VERSION ""

NS_ :

BS_:

BU_: TestNode
VAL_TABLE_ OperatingStatus 3 "Not Available" 2 "Not Operable" 1 "Derated Operation" 0 "Normal Operation" ;
VAL_TABLE_ ServiceIndicator 3 "Not Available" 2 "Reserved" 1 "Service Required" 0 "Service Not Required" ;
VAL_TABLE_ CommandStatus 3 "Not Available" 2 "Default Command" 1 "External Command" 0 "Internal Command" ;
VAL_TABLE_ StatusReasonLegacy 12 "Operating at Max Control Effort" 11 "Operating at Amp Limit" 10 "Unused" 9 "Over-Temp Protection Shutdown" 8 "Unused" 7 "Under-Voltage Protection Shutdn" 6 "Over Voltage Protection Shutdown" 5 "Unused" 4 "Unable to Start" 3 "Unused" 2 "Unused" 1 "Unused" 0 "OK/ Normal Operation" ;
VAL_TABLE_ StatusReason 6 "Speed Limit due to max cap" 5 "Speed Limit due to Amp Limit" 4 "Over-Temp Protection Shutdown" 3 "Under-Voltage Protection Shutdwn" 2 "Over-Voltage Protection Shutdown" 1 "Unable to Start" 0 "Normal Operation" ;
VAL_TABLE_ PowerHold 3 "Not Used" 2 "Reserved" 1 "Power On" 0 "Power Off" ;
VAL_TABLE_ OnOffDir 3 "Not Used" 2 "Motor On: Reverse" 1 "Motor On: Normal/Default Dir" 0 "Motor Off" ;

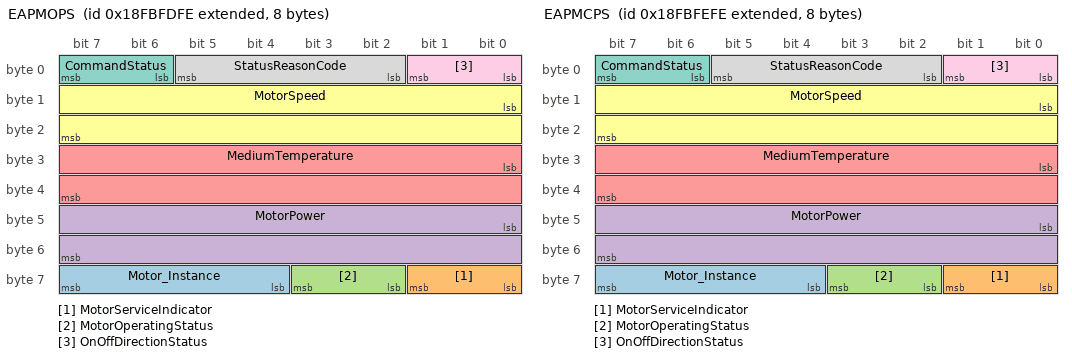
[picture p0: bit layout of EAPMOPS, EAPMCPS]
BO_ 2566651390 EAPMOPS: 8 Vector__XXX
 SG_ Motor_Instance : 60|4@1+ (1,0) [0|0] "" Vector__XXX
 SG_ MotorServiceIndicator : 56|2@1+ (1,0) [0|0] "" Vector__XXX
 SG_ MotorOperatingStatus : 58|2@1+ (1,0) [0|0] "" Vector__XXX
 SG_ MotorPower : 40|16@1+ (0.5,0) [0|0] "W" Vector__XXX
 SG_ MediumTemperature : 24|16@1+ (0.03125,-273) [0|0] "C" Vector__XXX
 SG_ MotorSpeed : 8|16@1+ (0.5,0) [0|0] "RPM" Vector__XXX
 SG_ CommandStatus : 6|2@1+ (1,0) [0|0] "" Vector__XXX
 SG_ StatusReasonCode : 2|4@1+ (1,0) [0|0] "" Vector__XXX
 SG_ OnOffDirectionStatus : 0|2@1+ (1,0) [0|0] "" Vector__XXX

BO_ 2566651646 EAPMCPS: 8 Vector__XXX
 SG_ Motor_Instance : 60|4@1+ (1,0) [0|0] "" Vector__XXX
 SG_ MotorServiceIndicator : 56|2@1+ (1,0) [0|0] "" Vector__XXX
 SG_ MotorOperatingStatus : 58|2@1+ (1,0) [0|0] "" Vector__XXX
 SG_ MotorPower : 40|16@1+ (0.5,0) [0|0] "W" Vector__XXX
 SG_ MediumTemperature : 24|16@1+ (0.03125,-273) [0|0] "C" Vector__XXX
 SG_ MotorSpeed : 8|16@1+ (0.5,0) [0|0] "RPM" Vector__XXX
 SG_ CommandStatus : 6|2@1+ (1,0) [0|0] "" Vector__XXX
 SG_ StatusReasonCode : 2|4@1+ (1,0) [0|0] "" Vector__XXX
 SG_ OnOffDirectionStatus : 0|2@1+ (1,0) [0|0] "" Vector__XXX

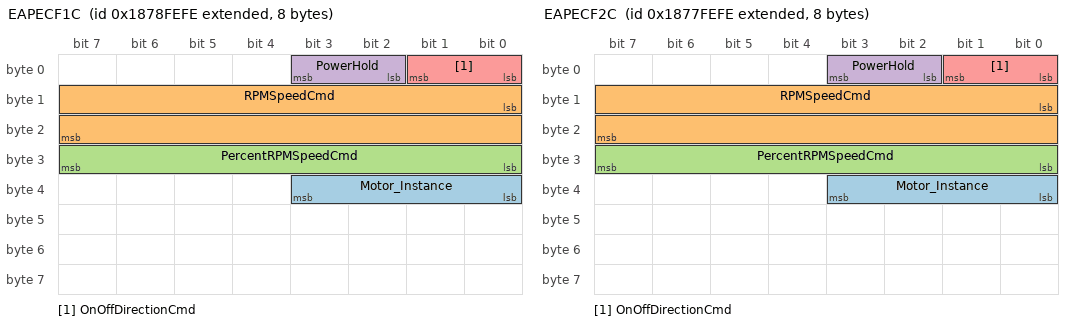
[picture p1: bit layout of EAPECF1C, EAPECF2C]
BO_ 2558066430 EAPECF1C: 8 Vector__XXX
 SG_ Motor_Instance : 32|4@1+ (1,0) [0|0] "" Vector__XXX
 SG_ RPMSpeedCmd : 8|16@1+ (0.5,0) [0|32127.5] "RPM" Vector__XXX
 SG_ PercentRPMSpeedCmd : 24|8@1+ (0.5,0) [0|125] "Pct" Vector__XXX
 SG_ PowerHold : 2|2@1+ (1,0) [0|3] "" Vector__XXX
 SG_ OnOffDirectionCmd : 0|2@1+ (1,0) [0|3] "" Vector__XXX

BO_ 2558000894 EAPECF2C: 8 Vector__XXX
 SG_ Motor_Instance : 32|4@1+ (1,0) [0|0] "" Vector__XXX
 SG_ RPMSpeedCmd : 8|16@1+ (0.5,0) [0|32127.5] "RPM" Vector__XXX
 SG_ PercentRPMSpeedCmd : 24|8@1+ (0.5,0) [0|125] "Pct" Vector__XXX
 SG_ PowerHold : 2|2@1+ (1,0) [0|3] "" Vector__XXX
 SG_ OnOffDirectionCmd : 0|2@1+ (1,0) [0|3] "" Vector__XXX

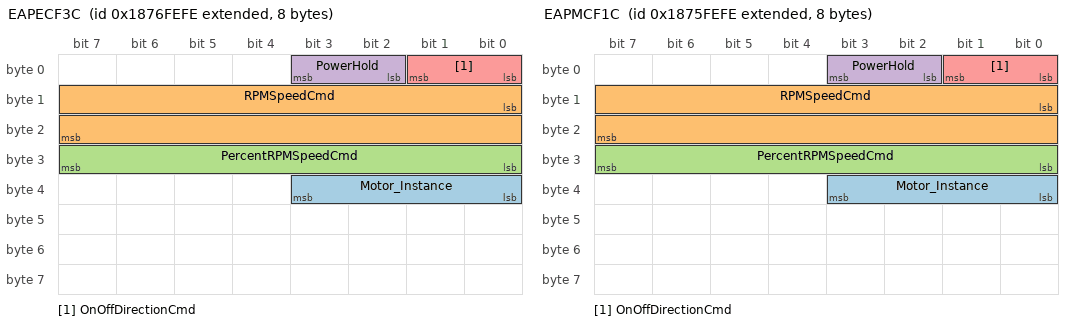
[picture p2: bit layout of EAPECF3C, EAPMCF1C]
BO_ 2557935358 EAPECF3C: 8 Vector__XXX
 SG_ Motor_Instance : 32|4@1+ (1,0) [0|0] "" Vector__XXX
 SG_ RPMSpeedCmd : 8|16@1+ (0.5,0) [0|32127.5] "RPM" Vector__XXX
 SG_ PercentRPMSpeedCmd : 24|8@1+ (0.5,0) [0|125] "Pct" Vector__XXX
 SG_ PowerHold : 2|2@1+ (1,0) [0|3] "" Vector__XXX
 SG_ OnOffDirectionCmd : 0|2@1+ (1,0) [0|3] "" Vector__XXX

BO_ 2557869822 EAPMCF1C: 8 Vector__XXX
 SG_ Motor_Instance : 32|4@1+ (1,0) [0|0] "" Vector__XXX
 SG_ RPMSpeedCmd : 8|16@1+ (0.5,0) [0|32127.5] "RPM" Vector__XXX
 SG_ PercentRPMSpeedCmd : 24|8@1+ (0.5,0) [0|125] "Pct" Vector__XXX
 SG_ PowerHold : 2|2@1+ (1,0) [0|3] "" Vector__XXX
 SG_ OnOffDirectionCmd : 0|2@1+ (1,0) [0|3] "" Vector__XXX

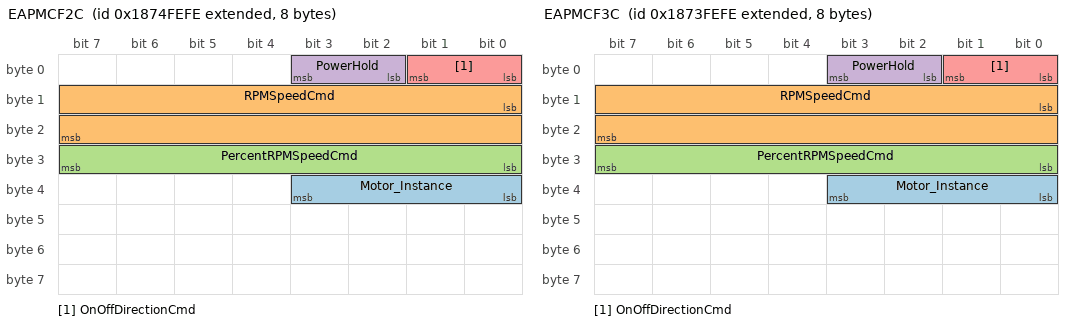
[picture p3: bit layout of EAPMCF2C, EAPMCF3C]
BO_ 2557804286 EAPMCF2C: 8 Vector__XXX
 SG_ Motor_Instance : 32|4@1+ (1,0) [0|0] "" Vector__XXX
 SG_ RPMSpeedCmd : 8|16@1+ (0.5,0) [0|32127.5] "RPM" Vector__XXX
 SG_ PercentRPMSpeedCmd : 24|8@1+ (0.5,0) [0|125] "Pct" Vector__XXX
 SG_ PowerHold : 2|2@1+ (1,0) [0|3] "" Vector__XXX
 SG_ OnOffDirectionCmd : 0|2@1+ (1,0) [0|3] "" Vector__XXX

BO_ 2557738750 EAPMCF3C: 8 Vector__XXX
 SG_ Motor_Instance : 32|4@1+ (1,0) [0|0] "" Vector__XXX
 SG_ RPMSpeedCmd : 8|16@1+ (0.5,0) [0|32127.5] "RPM" Vector__XXX
 SG_ PercentRPMSpeedCmd : 24|8@1+ (0.5,0) [0|125] "Pct" Vector__XXX
 SG_ PowerHold : 2|2@1+ (1,0) [0|3] "" Vector__XXX
 SG_ OnOffDirectionCmd : 0|2@1+ (1,0) [0|3] "" Vector__XXX

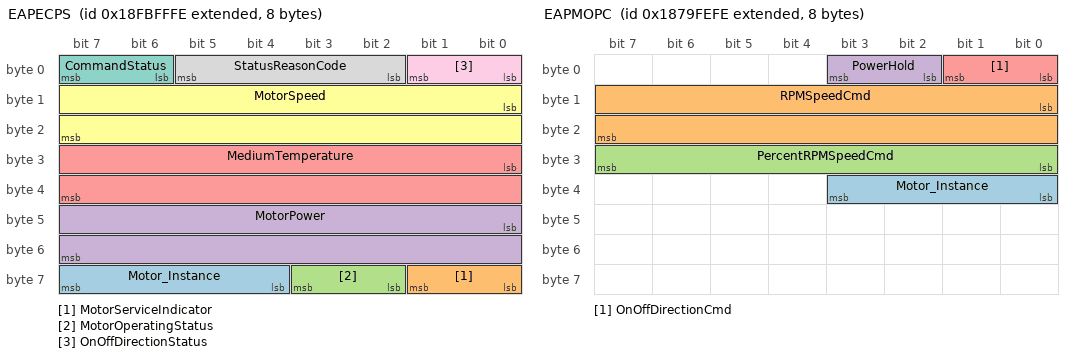
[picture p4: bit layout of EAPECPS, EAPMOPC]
BO_ 2566651902 EAPECPS: 8 Vector__XXX
 SG_ Motor_Instance : 60|4@1+ (1,0) [0|0] "" Vector__XXX
 SG_ MotorServiceIndicator : 56|2@1+ (1,0) [0|0] "" Vector__XXX
 SG_ MotorOperatingStatus : 58|2@1+ (1,0) [0|0] "" Vector__XXX
 SG_ MotorPower : 40|16@1+ (0.5,0) [0|0] "W" Vector__XXX
 SG_ MediumTemperature : 24|16@1+ (0.03125,-273) [0|0] "C" Vector__XXX
 SG_ MotorSpeed : 8|16@1+ (0.5,0) [0|0] "RPM" Vector__XXX
 SG_ CommandStatus : 6|2@1+ (1,0) [0|0] "" Vector__XXX
 SG_ StatusReasonCode : 2|4@1+ (1,0) [0|0] "" Vector__XXX
 SG_ OnOffDirectionStatus : 0|2@1+ (1,0) [0|0] "" Vector__XXX

BO_ 2558131966 EAPMOPC: 8 Vector__XXX
 SG_ Motor_Instance : 32|4@1+ (1,0) [0|0] "" Vector__XXX
 SG_ RPMSpeedCmd : 8|16@1+ (0.5,0) [0|32127.5] "RPM" Vector__XXX
 SG_ PercentRPMSpeedCmd : 24|8@1+ (0.5,0) [0|125] "Pct" Vector__XXX
 SG_ PowerHold : 2|2@1+ (1,0) [0|3] "" Vector__XXX
 SG_ OnOffDirectionCmd : 0|2@1+ (1,0) [0|3] "" Vector__XXX

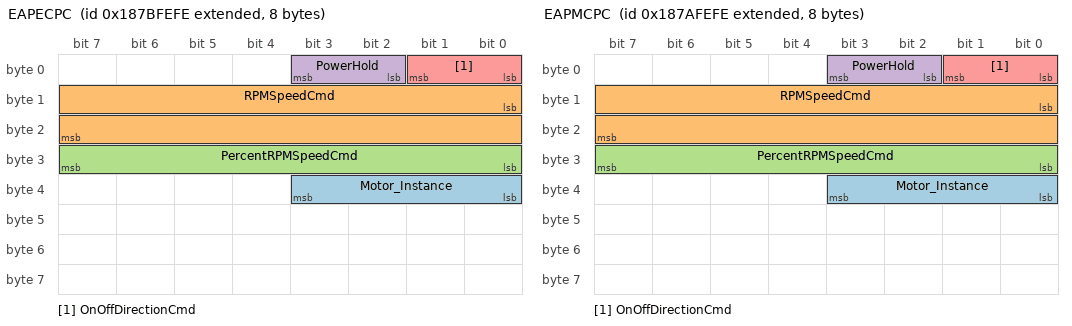
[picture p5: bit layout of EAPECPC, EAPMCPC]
BO_ 2558263038 EAPECPC: 8 Vector__XXX
 SG_ Motor_Instance : 32|4@1+ (1,0) [0|0] "" Vector__XXX
 SG_ RPMSpeedCmd : 8|16@1+ (0.5,0) [0|32127.5] "RPM" Vector__XXX
 SG_ PercentRPMSpeedCmd : 24|8@1+ (0.5,0) [0|125] "Pct" Vector__XXX
 SG_ PowerHold : 2|2@1+ (1,0) [0|3] "" Vector__XXX
 SG_ OnOffDirectionCmd : 0|2@1+ (1,0) [0|3] "" Vector__XXX

BO_ 2558197502 EAPMCPC: 8 Vector__XXX
 SG_ Motor_Instance : 32|4@1+ (1,0) [0|0] "" Vector__XXX
 SG_ RPMSpeedCmd : 8|16@1+ (0.5,0) [0|32127.5] "RPM" Vector__XXX
 SG_ PercentRPMSpeedCmd : 24|8@1+ (0.5,0) [0|127.5] "Pct" Vector__XXX
 SG_ PowerHold : 2|2@1+ (1,0) [0|3] "" Vector__XXX
 SG_ OnOffDirectionCmd : 0|2@1+ (1,0) [0|3] "" Vector__XXX

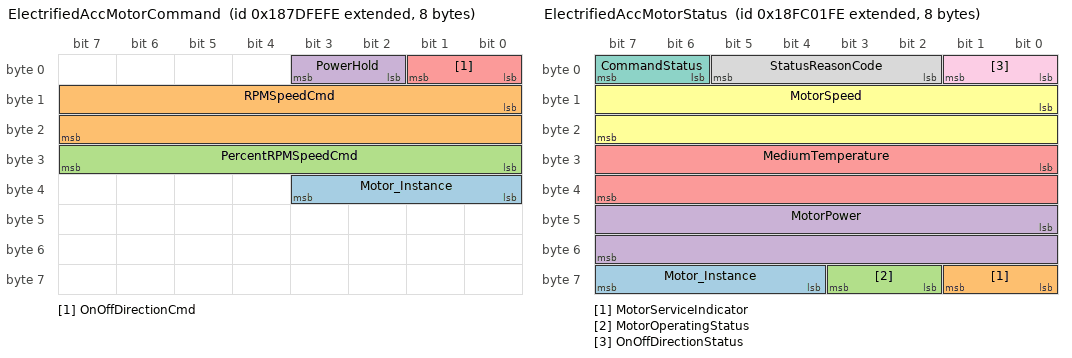
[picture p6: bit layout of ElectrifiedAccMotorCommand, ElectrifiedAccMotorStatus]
BO_ 2558394110 ElectrifiedAccMotorCommand: 8 TestNode
 SG_ Motor_Instance : 32|4@1+ (1,0) [0|0] "" Vector__XXX
 SG_ RPMSpeedCmd : 8|16@1+ (0.5,0) [0|32127.5] "RPM" Vector__XXX
 SG_ PercentRPMSpeedCmd : 24|8@1+ (0.5,0) [0|125] "Pct" Vector__XXX
 SG_ PowerHold : 2|2@1+ (1,0) [0|3] "" Vector__XXX
 SG_ OnOffDirectionCmd : 0|2@1+ (1,0) [0|3] "" Vector__XXX

BO_ 2566652414 ElectrifiedAccMotorStatus: 8 Vector__XXX
 SG_ Motor_Instance : 60|4@1+ (1,0) [0|0] "" Vector__XXX
 SG_ MotorServiceIndicator : 56|2@1+ (1,0) [0|0] "" Vector__XXX
 SG_ MotorOperatingStatus : 58|2@1+ (1,0) [0|0] "" Vector__XXX
 SG_ MotorPower : 40|16@1+ (0.5,0) [0|0] "W" Vector__XXX
 SG_ MediumTemperature : 24|16@1+ (0.03125,-273) [0|0] "C" Vector__XXX
 SG_ MotorSpeed : 8|16@1+ (0.5,0) [0|0] "RPM" Vector__XXX
 SG_ CommandStatus : 6|2@1+ (1,0) [0|0] "" Vector__XXX
 SG_ StatusReasonCode : 2|4@1+ (1,0) [0|0] "" Vector__XXX
 SG_ OnOffDirectionStatus : 0|2@1+ (1,0) [0|0] "" Vector__XXX

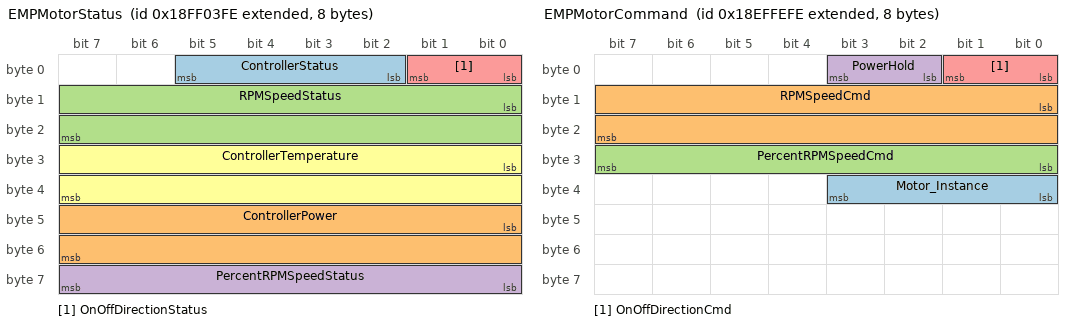
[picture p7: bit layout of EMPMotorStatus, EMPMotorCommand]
BO_ 2566849534 EMPMotorStatus: 8 Vector__XXX
 SG_ ControllerStatus : 2|4@1+ (1,0) [0|0] "" Vector__XXX
 SG_ ControllerPower : 40|16@1+ (1,0) [0|60000] "W" Vector__XXX
 SG_ RPMSpeedStatus : 8|16@1+ (0.5,0) [0|32127.5] "RPM" Vector__XXX
 SG_ PercentRPMSpeedStatus : 56|8@1+ (0.5,0) [0|125] "Pct" Vector__XXX
 SG_ OnOffDirectionStatus : 0|2@1+ (1,0) [0|3] "" Vector__XXX
 SG_ ControllerTemperature : 24|16@1+ (0.03125,-273) [-273|1734.96875] "C" Vector__XXX

BO_ 2565865214 EMPMotorCommand: 8 Vector__XXX
 SG_ Motor_Instance : 32|4@1+ (1,0) [0|0] "" Vector__XXX
 SG_ RPMSpeedCmd : 8|16@1+ (0.5,0) [0|32127.5] "RPM" Vector__XXX
 SG_ PercentRPMSpeedCmd : 24|8@1+ (0.5,0) [0|125] "Pct" Vector__XXX
 SG_ PowerHold : 2|2@1+ (1,0) [0|3] "" Vector__XXX
 SG_ OnOffDirectionCmd : 0|2@1+ (1,0) [0|3] "" Vector__XXX

BA_DEF_ SG_  "SigType" ENUM  "Default","Range","RangeSigned","ASCII","Discrete","Control","ReferencePGN","DTC","StringDelimiter","StringLength","StringLengthControl";
BA_DEF_ SG_  "GenSigEVName" STRING ;
BA_DEF_ SG_  "GenSigILSupport" ENUM  "Yes","No";
BA_DEF_ SG_  "GenSigSendType" ENUM  "Cyclic","OnWrite","reserved","OnChange","reserved","reserved","reserved","NoSigSendType";
BA_DEF_ SG_  "GenSigStartValue" INT 0 10000;
BA_DEF_ BO_  "GenMsgILSupport" ENUM  "Yes","No";
BA_DEF_ BU_  "NmStationAddress" INT 0 255;
BA_DEF_ BO_  "GenMsgSendType" ENUM  "cyclic","reserved","cyclicIfActive","reserved","reserved","reserved","reserved","reserved","noMsgSendType";
BA_DEF_ BO_  "GenMsgRequestable" INT 0 1;
BA_DEF_  "DBName" STRING ;
BA_DEF_  "BusType" STRING ;
BA_DEF_  "ProtocolType" STRING ;
BA_DEF_ BO_  "VFrameFormat" ENUM  "StandardCAN","ExtendedCAN","reserved","J1939PG";
BA_DEF_DEF_  "SigType" "Default";
BA_DEF_DEF_  "GenSigEVName" "Env@Nodename_@Signame";
BA_DEF_DEF_  "GenSigILSupport" "Yes";
BA_DEF_DEF_  "GenSigSendType" "NoSigSendType";
BA_DEF_DEF_  "GenSigStartValue" 0;
BA_DEF_DEF_  "GenMsgILSupport" "Yes";
BA_DEF_DEF_  "NmStationAddress" 254;
BA_DEF_DEF_  "GenMsgSendType" "noMsgSendType";
BA_DEF_DEF_  "GenMsgRequestable" 1;
BA_DEF_DEF_  "DBName" "";
BA_DEF_DEF_  "BusType" "CAN";
BA_DEF_DEF_  "ProtocolType" "J1939";
BA_DEF_DEF_  "VFrameFormat" "J1939PG";
BA_ "DBName" "EMP_CAN3";
BA_ "NmStationAddress" BU_ TestNode 119;
BA_ "GenSigStartValue" SG_ 2566651390 MediumTemperature 8736;
BA_ "GenSigStartValue" SG_ 2566651646 MediumTemperature 8736;
BA_ "GenSigStartValue" SG_ 2566651902 MediumTemperature 8736;
BA_ "GenSigStartValue" SG_ 2566652414 MediumTemperature 8736;
BA_ "GenSigStartValue" SG_ 2566849534 ControllerTemperature 8736;
VAL_ 2566651390 MotorServiceIndicator 3 "Not Available" 2 "Reserved" 1 "Service Required" 0 "Service Not Required" ;
VAL_ 2566651390 MotorOperatingStatus 3 "Not Available" 2 "Not Operable" 1 "Derated Operation" 0 "Normal Operation" ;
VAL_ 2566651390 CommandStatus 3 "Not Available" 2 "Default Command" 1 "External Command" 0 "Internal Command" ;
VAL_ 2566651390 StatusReasonCode 7 "Speed Limit for stall protect" 6 "Speed Limit due to max cap" 5 "Speed Limit due to Amp Limit" 4 "Over-Temp Protection Shutdown" 3 "Under-Voltage Protection Shutdwn" 2 "Over-Voltage Protection Shutdown" 1 "Unable to Start" 0 "Normal Operation" ;
VAL_ 2566651390 OnOffDirectionStatus 3 "Not Used" 2 "Motor On: Reverse" 1 "Motor On: Normal/Default Dir" 0 "Motor Off" ;
VAL_ 2566651646 MotorServiceIndicator 3 "Not Available" 2 "Reserved" 1 "Service Required" 0 "Service Not Required" ;
VAL_ 2566651646 MotorOperatingStatus 3 "Not Available" 2 "Not Operable" 1 "Derated Operation" 0 "Normal Operation" ;
VAL_ 2566651646 CommandStatus 3 "Not Available" 2 "Default Command" 1 "External Command" 0 "Internal Command" ;
VAL_ 2566651646 StatusReasonCode 7 "Speed Limit for stall protect" 6 "Speed Limit due to max cap" 5 "Speed Limit due to Amp Limit" 4 "Over-Temp Protection Shutdown" 3 "Under-Voltage Protection Shutdwn" 2 "Over-Voltage Protection Shutdown" 1 "Unable to Start" 0 "Normal Operation" ;
VAL_ 2566651646 OnOffDirectionStatus 3 "Not Used" 2 "Motor On: Reverse" 1 "Motor On: Normal/Default Dir" 0 "Motor Off" ;
VAL_ 2558066430 PowerHold 3 "Not Used" 2 "Reserved" 1 "Power On" 0 "Power Off" ;
VAL_ 2558066430 OnOffDirectionCmd 3 "Not Used" 2 "Motor On: Reverse" 1 "Motor On: Normal/Default Dir" 0 "Motor Off" ;
VAL_ 2558000894 PowerHold 3 "Not Used" 2 "Reserved" 1 "Power On" 0 "Power Off" ;
VAL_ 2558000894 OnOffDirectionCmd 3 "Not Used" 2 "Motor On: Reverse" 1 "Motor On: Normal/Default Dir" 0 "Motor Off" ;
VAL_ 2557935358 PowerHold 3 "Not Used" 2 "Reserved" 1 "Power On" 0 "Power Off" ;
VAL_ 2557935358 OnOffDirectionCmd 3 "Not Used" 2 "Motor On: Reverse" 1 "Motor On: Normal/Default Dir" 0 "Motor Off" ;
VAL_ 2557869822 PowerHold 3 "Not Used" 2 "Reserved" 1 "Power On" 0 "Power Off" ;
VAL_ 2557869822 OnOffDirectionCmd 3 "Not Used" 2 "Motor On: Reverse" 1 "Motor On: Normal/Default Dir" 0 "Motor Off" ;
VAL_ 2557804286 PowerHold 3 "Not Used" 2 "Reserved" 1 "Power On" 0 "Power Off" ;
VAL_ 2557804286 OnOffDirectionCmd 3 "Not Used" 2 "Motor On: Reverse" 1 "Motor On: Normal/Default Dir" 0 "Motor Off" ;
VAL_ 2557738750 PowerHold 3 "Not Used" 2 "Reserved" 1 "Power On" 0 "Power Off" ;
VAL_ 2557738750 OnOffDirectionCmd 3 "Not Used" 2 "Motor On: Reverse" 1 "Motor On: Normal/Default Dir" 0 "Motor Off" ;
VAL_ 2566651902 MotorServiceIndicator 3 "Not Available" 2 "Reserved" 1 "Service Required" 0 "Service Not Required" ;
VAL_ 2566651902 MotorOperatingStatus 3 "Not Available" 2 "Not Operable" 1 "Derated Operation" 0 "Normal Operation" ;
VAL_ 2566651902 CommandStatus 3 "Not Available" 2 "Default Command" 1 "External Command" 0 "Internal Command" ;
VAL_ 2566651902 StatusReasonCode 7 "Speed Limit for stall protect" 6 "Speed Limit due to max cap" 5 "Speed Limit due to Amp Limit" 4 "Over-Temp Protection Shutdown" 3 "Under-Voltage Protection Shutdwn" 2 "Over-Voltage Protection Shutdown" 1 "Unable to Start" 0 "Normal Operation" ;
VAL_ 2566651902 OnOffDirectionStatus 3 "Not Used" 2 "Motor On: Reverse" 1 "Motor On: Normal/Default Dir" 0 "Motor Off" ;
VAL_ 2558131966 PowerHold 3 "Not Used" 2 "Reserved" 1 "Power On" 0 "Power Off" ;
VAL_ 2558131966 OnOffDirectionCmd 3 "Not Used" 2 "Motor On: Reverse" 1 "Motor On: Normal/Default Dir" 0 "Motor Off" ;
VAL_ 2558263038 PowerHold 3 "Not Used" 2 "Reserved" 1 "Power On" 0 "Power Off" ;
VAL_ 2558263038 OnOffDirectionCmd 3 "Not Used" 2 "Motor On: Reverse" 1 "Motor On: Normal/Default Dir" 0 "Motor Off" ;
VAL_ 2558197502 PowerHold 3 "Not Used" 2 "Reserved" 1 "Power On" 0 "Power Off" ;
VAL_ 2558197502 OnOffDirectionCmd 3 "Not Used" 2 "Motor On: Reverse" 1 "Motor On: Normal/Default Dir" 0 "Motor Off" ;
VAL_ 2558394110 PowerHold 3 "Not Used" 2 "Reserved" 1 "Power On" 0 "Power Off" ;
VAL_ 2558394110 OnOffDirectionCmd 3 "Not Used" 2 "Motor On: Reverse" 1 "Motor On: Normal/Default Dir" 0 "Motor Off" ;
VAL_ 2566652414 MotorServiceIndicator 3 "Not Available" 2 "Reserved" 1 "Service Required" 0 "Service Not Required" ;
VAL_ 2566652414 MotorOperatingStatus 3 "Not Available" 2 "Not Operable" 1 "Derated Operation" 0 "Normal Operation" ;
VAL_ 2566652414 CommandStatus 3 "Not Available" 2 "Default Command" 1 "External Command" 0 "Internal Command" ;
VAL_ 2566652414 StatusReasonCode 7 "Speed Limit for stall protect" 6 "Speed Limit due to max cap" 5 "Speed Limit due to Amp Limit" 4 "Over-Temp Protection Shutdown" 3 "Under-Voltage Protection Shutdwn" 2 "Over-Voltage Protection Shutdown" 1 "Unable to Start" 0 "Normal Operation" ;
VAL_ 2566652414 OnOffDirectionStatus 3 "Not Used" 2 "Motor On: Reverse" 1 "Motor On: Normal/Default Dir" 0 "Motor Off" ;
VAL_ 2566849534 ControllerStatus 12 "Operating at Max Control Effort" 11 "Operating at Amp Limit" 10 "Unused" 9 "Over-Temp Protection Shutdown" 8 "Unused" 7 "Under-Voltage Protection Shutdn" 6 "Over Voltage Protection Shutdown" 5 "Unused" 4 "Unable to Start" 3 "Unused" 2 "Unused" 1 "Unused" 0 "OK/ Normal Operation" ;
VAL_ 2566849534 OnOffDirectionStatus 3 "Not Used" 2 "Motor On: Reverse" 1 "Motor On: Normal/Default Dir" 0 "Motor Off" ;
VAL_ 2565865214 PowerHold 3 "Not Used" 2 "Reserved" 1 "Power On" 0 "Power Off" ;
VAL_ 2565865214 OnOffDirectionCmd 3 "Not Used" 2 "Motor On: Reverse" 1 "Motor On: Normal/Default Dir" 0 "Motor Off" ;
